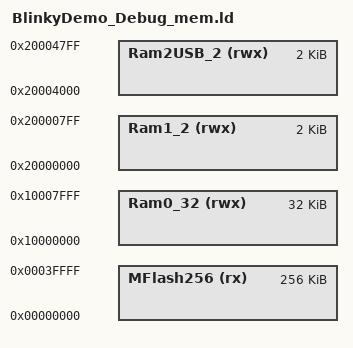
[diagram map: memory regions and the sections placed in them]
/*
 * GENERATED FILE - DO NOT EDIT
 * (c) Code Red Technologies Ltd, 2008-2015
 * (c) NXP Semiconductors 2013-2015
 * Linker script memory definitions
 * Created from LinkMemoryTemplate
 * By LPCXpresso v7.5.0 [Build 254] [2014-10-31]  on Tue Feb 10 14:12:50 CET 2015)
*/

MEMORY
{
  /* Define each memory region */
  MFlash256 (rx) : ORIGIN = 0x0, LENGTH = 0x40000 /* 256K bytes */
  Ram0_32 (rwx) : ORIGIN = 0x10000000, LENGTH = 0x8000 /* 32K bytes */
  Ram1_2 (rwx) : ORIGIN = 0x20000000, LENGTH = 0x800 /* 2K bytes */
  Ram2USB_2 (rwx) : ORIGIN = 0x20004000, LENGTH = 0x800 /* 2K bytes */


}
  /* Define a symbol for the top of each memory region */
  __top_MFlash256 = 0x0 + 0x40000;
  __top_Ram0_32 = 0x10000000 + 0x8000;
  __top_Ram1_2 = 0x20000000 + 0x800;
  __top_Ram2USB_2 = 0x20004000 + 0x800;



